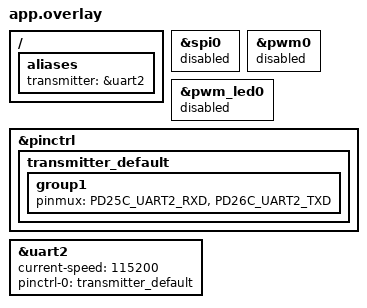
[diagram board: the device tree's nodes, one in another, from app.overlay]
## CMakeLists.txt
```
cmake_minimum_required(VERSION 3.20.0)

include("../../settings.cmake")

# Receiver-specific devicetree overlay: UART2 only (see app.overlay).
# Must be set BEFORE find_package(Zephyr).
set(DTC_OVERLAY_FILE "${CMAKE_CURRENT_LIST_DIR}/app.overlay")

find_package(Zephyr)
project(CDH_RX)

target_sources(app
        PRIVATE
        src/main.c
        ../../MIDDLEWARE/UART/uart_transport.c
)

# Same ASN.1 schemas as CDH_App so both ends of the link always agree on the
# wire format. (No POST_BUILD icd.html copy here; CDH_App already does that.)
include("../../MIDDLEWARE/ASN1SCC/asn1scc.cmake")

asn1scc_generate_c(app
        ../../APP/_asn1/_systems.asn1
        ../../APP/_asn1/bms.asn1
        ../../APP/_asn1/pds.asn1
        ../../APP/_asn1/comms.asn1
        EXTRA_OPTS --slim -sm
)

target_include_directories(app PRIVATE
        ${CMAKE_CURRENT_SOURCE_DIR}/../../MIDDLEWARE/UART/include
)
```

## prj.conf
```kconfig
# Receiver app: UART2 + logging only. I2C/SPI/PWM/LED are off.
CONFIG_ARM_MPU=y
CONFIG_BUILD_OUTPUT_COMPRESS_DEBUG_SECTIONS=y
CONFIG_BUILD_OUTPUT_HEX=y
CONFIG_CACHE_MANAGEMENT=y
CONFIG_CBPRINTF_FP_SUPPORT=y
CONFIG_CONSOLE=y
CONFIG_DEBUG_OPTIMIZATIONS=y
CONFIG_GPIO=y
CONFIG_HW_STACK_PROTECTION=y
CONFIG_I2C=n
CONFIG_LED=n
CONFIG_LFP=y
CONFIG_LOG=y
CONFIG_LOG_BACKEND_UART_OUTPUT_DICTIONARY=y
CONFIG_LOG_BUFFER_SIZE=4096
CONFIG_LOG_DBG_COLOR_BLUE=y
CONFIG_LOG_FUNC_NAME_PREFIX_ERR=y
CONFIG_LOG_FUNC_NAME_PREFIX_INF=y
CONFIG_LOG_FUNC_NAME_PREFIX_WRN=y
CONFIG_LOG_OUTPUT=y
CONFIG_LOG_PROCESS_THREAD_SLEEP_MS=10
CONFIG_MAIN_STACK_SIZE=2048
CONFIG_PWM=n
CONFIG_SERIAL=y
CONFIG_SPI=n
CONFIG_THREAD_MONITOR=y
CONFIG_THREAD_NAME=y
CONFIG_UART_CONSOLE=y
CONFIG_UART_INTERRUPT_DRIVEN=y
CONFIG_WDT_DISABLE_AT_BOOT=y
```

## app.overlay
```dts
/*
 * Receiver board overlay: UART2 only.
 *
 * The pinctrl and uart2 blocks at the bottom are copied verbatim from
 * CDH_App/app.overlay. If you change the baud rate or pins in one file,
 * change the other too, or the two boards will stop understanding each other.
 */
/ {
    aliases {
        transmitter = &uart2;
    };
};

/* Disabled for the same reason as in CDH_App/app.overlay: these conflict with
 * the UART2 configuration below. */
&spi0 {
    status = "disabled";
};

&pwm0 {
    status = "disabled";
};

&pwm_led0 {
    status = "disabled";
};

&pinctrl {
    transmitter_default: transmitter_default {
        group1 {
            pinmux = <PD25C_UART2_RXD>,
                     <PD26C_UART2_TXD>;
        };
    };
};

&uart2 {
    status = "okay";
    // Setting this to 500000 was causing the UART to drop bytes, so it was changed to 115200 for now. This may need to be revisited in the future.
    current-speed = <115200>;

    pinctrl-0 = <&transmitter_default>;
    pinctrl-names = "default";
};
```

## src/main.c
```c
#include <stdio.h>

#include <asn1_lfp.h>
#include <asn1/bms.h>
#include <asn1/pds.h>
#include <asn1/_systems.h>

#include "asn1/comms.h"
#include "uart/uart_transport.h"
#include "lfp/stream.h"
#include "zephyr/kernel.h"
#include "zephyr/logging/log.h"

LOG_MODULE_REGISTER(cdh, LOG_LEVEL_DBG);

/*
 * UART2 link to the other board. Uses the same `transmitter` devicetree alias
 * as CDH_App (shared overlay), so both images get the same peripheral, pins
 * and baud rate.
 */
#if DT_NODE_HAS_STATUS(DT_ALIAS(transmitter), okay)
static const struct device *const link_uart = DEVICE_DT_GET(DT_ALIAS(transmitter));
#else
#error "transmitter devicetree alias is not defined/enabled - check the shared overlay"
#endif

typedef struct
{
    lfp_header_t *p_header;
    uint8_t rx_history[32];
    uint8_t rx_history_next;
    uint8_t rx_history_count;
} user_ctx_t;

static inline double cdh_adc_to_float(const uint16_t value)
{
    return ((double)value * 3.3) / (1 << 12);
}

static void cdh_bms_system_status_callback(
    BMSSystemStatusResponse *payload,
    asn1_lfp_decode_data_t *data
)
{
    ARG_UNUSED(data);
    LOG_DBG(
        "BMS System Status:\n\tVersion: %d\n\tUptime: 0x%x",
        payload->version,
        payload->uptime
    );
}

static void cdh_bms_power_status_callback(
    BMSPowerStatusResponse *payload,
    asn1_lfp_decode_data_t *data
)
{
    ARG_UNUSED(data);

    for (int pack_id = 1; pack_id <= 2; ++pack_id) {
        const BMSBatteryPackStatus *pack = pack_id == 1
            ? &payload->batteryPack1
            : &payload->batteryPack2;

        LOG_DBG(
            "Battery %d:\n\tVoltage: %.3f | Current Draw: %.3f | "
            "Current Charge: %.3f | Overcurrent: %d\n"
            "\tCell A:\n\t\tVoltage: %.3f\n\t\tOV/UV: %d/%d\n"
            "\tCell B:\n\t\tVoltage: %.3f\n\t\tOV/UV: %d/%d",
            pack_id,
            cdh_adc_to_float(pack->voltage),
            cdh_adc_to_float(pack->currentDraw),
            cdh_adc_to_float(pack->currentCharge),
            pack->overcurrent,
            cdh_adc_to_float(pack->cellA.voltage),
            pack->cellA.overvoltage,
            pack->cellA.undervoltage,
            cdh_adc_to_float(pack->cellB.voltage),
            pack->cellB.overvoltage,
            pack->cellB.undervoltage
        );
    }
}

static void cdh_bms_temperature_status_callback(
    BMSTemperatureStatusResponse *payload,
    asn1_lfp_decode_data_t *data
)
{
    ARG_UNUSED(data);
    LOG_DBG(
        "BMS Temperature Status: "
        "T1=%u T2=%u T3=%u T4=%u T5=%u T6=%u T7=%u T8=%u",
        payload->thermistors.arr[0],
        payload->thermistors.arr[1],
        payload->thermistors.arr[2],
        payload->thermistors.arr[3],
        payload->thermistors.arr[4],
        payload->thermistors.arr[5],
        payload->thermistors.arr[6],
        payload->thermistors.arr[7]
    );
}

static void cdh_pds_system_status_callback(
    PDSSystemStatusResponse *payload,
    asn1_lfp_decode_data_t *data
)
{
    ARG_UNUSED(data);
    LOG_DBG(
        "PDS System Status:\n\tVersion: %d\n\tUptime: 0x%x",
        payload->version,
        payload->uptime
    );
}

static void cdh_pds_health_check_callback(
    PDSHealthCheckResponse *payload,
    asn1_lfp_decode_data_t *data
)
{
    ARG_UNUSED(data);
#ifdef LOG_LEVEL_DBG
    uint8_t hash[sizeof(payload->hash.arr) / sizeof(payload->hash.arr[0])];

    for (size_t i = 0; i < sizeof(hash); ++i) {
        hash[i] = (uint8_t)payload->hash.arr[i];
    }

    LOG_HEXDUMP_DBG(hash, sizeof(hash), "PDS Health Check Hash:");
#endif
}

static void cdh_pds_converter_monitor_callback(
    PDSConverterMonitorResponse *payload,
    asn1_lfp_decode_data_t *data
)
{
    ARG_UNUSED(data);
    LOG_DBG(
        "PDS Converter Monitor:\n"
        "\tint5vVs: %.3f V\n"
        "\treg5vVs: %.3f V\n"
        "\tconverterA5vVs: %.3f V\n"
        "\tconverterB5vVs: %.3f V\n"
        "\ttemperatureSense: %.3f V\n",
        cdh_adc_to_float(payload->int5vVs),
        cdh_adc_to_float(payload->reg5vVs),
        cdh_adc_to_float(payload->converterA5vVs),
        cdh_adc_to_float(payload->converterB5vVs),
        cdh_adc_to_float(payload->temperatureSense)
    );
}

void target_to_str(uint8_t target, char *buf, size_t buf_size)
{
    if (target == cdhSystemId) {
        snprintf(buf, buf_size, "CDH(%d)", target);
    } else if (target == bmsSystemId) {
        snprintf(buf, buf_size, "BMS(%d)", target);
    } else if (target == pdsSystemId) {
        snprintf(buf, buf_size, "PDS(%d)", target);
    } else {
        snprintf(buf, buf_size, "Unknown(%d)", target);
    }
}

void endpoint_to_str(uint8_t endpoint, char *buf, size_t buf_size)
{
    if (endpoint == lfpIdBMSPowerStatusResponse) {
        snprintf(buf, buf_size, "BMSPowerStatusResponse");
    } else if (endpoint == lfpIdBMSSystemStatusResponse) {
        snprintf(buf, buf_size, "BMSSystemStatusResponse");
    } else if (endpoint == lfpIdBMSTemperatureStatusResponse) {
        snprintf(buf, buf_size, "BMSTemperatureStatusResponse");
    } else if (endpoint == lfpIdPDSSystemStatusResponse) {
        snprintf(buf, buf_size, "PDSSystemStatusResponse");
    } else if (endpoint == lfpIdPDSHealthCheckResponse) {
        snprintf(buf, buf_size, "PDSHealthCheckResponse");
    } else if (endpoint == lfpIdPDSConverterMonitorResponse) {
        snprintf(buf, buf_size, "PDSConverterMonitorResponse");
    } else {
        snprintf(buf, buf_size, "Unknown(%d)", endpoint);
    }
}

static void cdh_asn1_error_callback(
    int error_code,
    const asn1_lfp_decode_data_t *data
)
{

    char target[16];
    char endpoint[16];
    target_to_str(data->p_header->target, target, sizeof(target));
    endpoint_to_str(data->p_header->endpoint, endpoint, sizeof(endpoint));
    LOG_WRN("CDH ASN.1 parse failed, error_code=%d, target=%s, endpoint=%s", error_code, target, endpoint);
}

#define ASN1_RESPONSE_MESSAGES(X) \
X(bmsSystemId, BMSSystemStatusResponse, cdh_bms_system_status_callback) \
X(bmsSystemId, BMSPowerStatusResponse, cdh_bms_power_status_callback) \
X(bmsSystemId, BMSTemperatureStatusResponse, cdh_bms_temperature_status_callback) \
X(pdsSystemId, PDSSystemStatusResponse, cdh_pds_system_status_callback) \
X(pdsSystemId, PDSHealthCheckResponse, cdh_pds_health_check_callback) \
X(pdsSystemId, PDSConverterMonitorResponse, cdh_pds_converter_monitor_callback)

#define TRY_ASN1_MESSAGE(target, type, callback) \
if (ASN1_LFP_HANDLE_MSG(tmp, target, type, callback)) return true;

static bool decode_message(asn1_lfp_decode_data_t *data)
{
    asn1_lfp_decode_data_t tmp = *data;
    ASN1_RESPONSE_MESSAGES(TRY_ASN1_MESSAGE)

    return false;
}

static bool receiver_on_header(const lfp_header_t *header, void *user_data)
{
    user_ctx_t* ctx = user_data;
    ctx->p_header = (lfp_header_t*)header;
    LOG_DBG("Received header: length=%d initiator=%d target=%d endpoint=%d",
        header->encoded_length,
        header->initiator,
        header->target,
        header->endpoint
    );
    return true;
}

static void receiver_on_message(
    const lfp_header_t *header,
    const uint8_t *body,
    uint16_t body_length,
    void *user_data
)
{
    ARG_UNUSED(user_data);

    LOG_DBG(
        "receiver telemetry: target=%d endpoint=%d",
        header->target,
        header->endpoint
    );

    asn1_lfp_decode_data_t data = {
        .p_on_error_cb = cdh_asn1_error_callback,
        .p_header = header,
        .p_body = body,
        .body_length = body_length
    };
    decode_message(&data);
}


static void receiver_on_error(lfp_code_t reason, void *user_data)
{
    user_ctx_t *ctx = user_data;
    LOG_WRN("receiver LFP stream error detected: %d", reason);

    // Print the last 32 bytes received over UART
    uint8_t history[sizeof(ctx->rx_history)];
    for (size_t i = 0; i < ctx->rx_history_count; ++i) {
        const size_t index = (ctx->rx_history_next + sizeof(ctx->rx_history)
                              - ctx->rx_history_count + i)
                             % sizeof(ctx->rx_history);
        history[i] = ctx->rx_history[index];
    }
    LOG_HEXDUMP_WRN(history, ctx->rx_history_count,
                    "UART bytes preceding and including error:");

    // Print the last 128 bytes captured by the UART RX ISR for comparison
    uint8_t raw_history[128];
    const size_t raw_count = uart_transport_debug_snapshot(
        raw_history, sizeof(raw_history));
    LOG_HEXDUMP_WRN(raw_history, raw_count,
                    "Raw UART bytes captured by RX ISR:");

    const uint32_t dropped = uart_transport_debug_dropped();
    if (dropped != 0) {
        LOG_WRN("UART RX ring has dropped %u bytes", dropped);
    }
}

K_SEM_DEFINE(transmit_sem, 0, 1);

static void transmit_thread(const void *p)
{
    ARG_UNUSED(p);

    COMMSDummyRequest dummy_request = {
        .placeholder = 0xDEADBEEF
    };

    k_sem_take(&transmit_sem, K_FOREVER);
    uint8_t encode_buf[ASN1_LFP_SEND_BUF_SIZE(COMMSDummyRequest)];
    const uint32_t size = ASN1_LFP_SERIALIZE(commsSystemId, cdhSystemId, COMMSDummyRequest, encode_buf, sizeof(encode_buf), dummy_request);
    if (!size)
    {
        LOG_WRN("Failed to serialize COMMS dummy request");
        return;
    }

    while (1) {
        LOG_DBG("Transmitting COMMS dummy request telemetry");
        uart_transport_write(link_uart, encode_buf, size);

        k_sleep(K_MSEC(3000));
    }
}

K_THREAD_DEFINE(p_tramsit_thread, 1024, transmit_thread, NULL, NULL, NULL,
        3, 0, 2000);

int main(void)
{
    uint8_t uart_rx_byte;
    static uint8_t lfp_body_buffer[256];
    lfp_stream_ctx_t lfp_stream;
    user_ctx_t usr_ctx = {0};

    lfp_stream_init(
        &lfp_stream,
        lfp_body_buffer,
        sizeof(lfp_body_buffer),
        receiver_on_header,
        receiver_on_message,
        receiver_on_error,
        &usr_ctx
    );



    LOG_INF("Opening uart transport");
    int ret = uart_transport_open(link_uart);
    if (ret != 0) {
        LOG_ERR("Failed to open UART2 RX: %d", ret);
        return ret;
    }

    LOG_INF("Starting UART2 receiver (decoding telemetry from CDH_App board)");
    k_sem_give(&transmit_sem);

    while (1) {
        ret = uart_transport_read(
            &uart_rx_byte,
            sizeof(uart_rx_byte),
            K_FOREVER
        );
        if (ret < 0) {
            LOG_WRN("Failed to read from UART2: %d", ret);
            continue;
        }
        if (ret == 0) {
            continue;
        }

        usr_ctx.rx_history[usr_ctx.rx_history_next] = uart_rx_byte;
        usr_ctx.rx_history_next =
            (usr_ctx.rx_history_next + 1) % sizeof(usr_ctx.rx_history);
        if (usr_ctx.rx_history_count < sizeof(usr_ctx.rx_history)) {
            usr_ctx.rx_history_count++;
        }

        lfp_stream_update(&lfp_stream, uart_rx_byte);
    }
}
```
